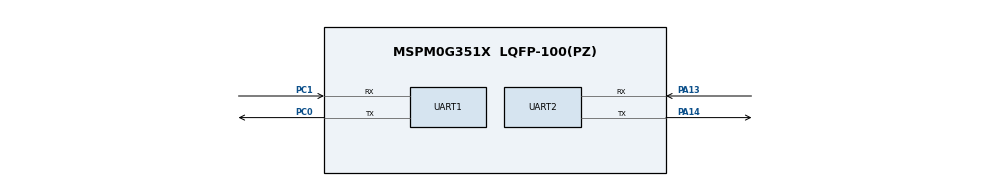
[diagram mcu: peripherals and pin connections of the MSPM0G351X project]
/**
 * @cliArgs --device "MSPM0G351X" --part "Default" --package "LQFP-100(PZ)" --product "mspm0_sdk@2.07.00.05"
 * @versions {"tool":"1.27.0+4565"}
 */

/**
 * Import the modules used in this configuration.
 */
const ADC12         = scripting.addModule("/ti/driverlib/ADC12", {}, false);
const ADC121        = ADC12.addInstance();
const SYSCTL        = scripting.addModule("/ti/driverlib/SYSCTL");
const TIMER         = scripting.addModule("/ti/driverlib/TIMER", {}, false);
const TIMER1        = TIMER.addInstance();
const UART          = scripting.addModule("/ti/driverlib/UART", {}, false);
const UART1         = UART.addInstance();
const UART2         = UART.addInstance();
const ProjectConfig = scripting.addModule("/ti/project_config/ProjectConfig");

/**
 * Write custom configuration values to the imported modules.
 */
const divider9       = system.clockTree["UDIV"];
divider9.divideValue = 2;

const mux4       = system.clockTree["EXHFMUX"];
mux4.inputSelect = "EXHFMUX_XTAL";

const mux8       = system.clockTree["HSCLKMUX"];
mux8.inputSelect = "HSCLKMUX_SYSPLL2X";

const mux12       = system.clockTree["SYSPLLMUX"];
mux12.inputSelect = "zSYSPLLMUX_HFCLK";

const pinFunction4       = system.clockTree["HFXT"];
pinFunction4.inputFreq   = 40;
pinFunction4.enable      = true;
pinFunction4.HFXTStartup = 10;

ADC121.$name                             = "ADC12_0";
ADC121.sampClkSrc                        = "DL_ADC12_CLOCK_ULPCLK";
ADC121.repeatMode                        = true;
ADC121.trigSrc                           = "DL_ADC12_TRIG_SRC_EVENT";
ADC121.adcMem0trig                       = "DL_ADC12_TRIGGER_MODE_TRIGGER_NEXT";
ADC121.powerDownMode                     = "DL_ADC12_POWER_DOWN_MODE_MANUAL";
ADC121.sampleTime0                       = "50 ns";
ADC121.enabledInterrupts                 = ["DL_ADC12_INTERRUPT_DMA_DONE"];
ADC121.configureDMA                      = true;
ADC121.sampCnt                           = 1;
ADC121.enabledDMATriggers                = ["DL_ADC12_DMA_MEM0_RESULT_LOADED"];
ADC121.adcMem0chansel                    = "DL_ADC12_INPUT_CHAN_5";
ADC121.subChanID                         = 1;
ADC121.DMA_CHANNEL.$name                 = "DMA_CH0";
ADC121.DMA_CHANNEL.addressMode           = "f2b";
ADC121.DMA_CHANNEL.srcLength             = "HALF_WORD";
ADC121.DMA_CHANNEL.dstLength             = "HALF_WORD";
ADC121.DMA_CHANNEL.configureTransferSize = true;
ADC121.DMA_CHANNEL.transferMode          = "FULL_CH_REPEAT_SINGLE";
ADC121.DMA_CHANNEL.transferSize          = 1024;
ADC121.adcPin5Config.$name               = "ti_driverlib_gpio_GPIOPinGeneric0";

const Board = scripting.addModule("/ti/driverlib/Board", {}, false);

SYSCTL.forceDefaultClkConfig = true;
SYSCTL.clockTreeEn           = true;

TIMER1.$name                       = "TIMER_0";
TIMER1.timerClkDiv                 = 8;
TIMER1.timerMode                   = "PERIODIC_UP";
TIMER1.timerPeriod                 = "800 ns";
TIMER1.event1PublisherChannel      = 1;
TIMER1.event1ControllerInterruptEn = ["ZERO_EVENT"];

UART1.enabledInterrupts                = ["RX"];
UART1.$name                            = "UART_TJC";
UART1.peripheral.$assign               = "UART1";
UART1.peripheral.rxPin.$assign         = "PC1";
UART1.peripheral.txPin.$assign         = "PC0";
UART1.txPinConfig.$name                = "ti_driverlib_gpio_GPIOPinGeneric1";
UART1.txPinConfig.direction            = scripting.forceWrite("OUTPUT");
UART1.txPinConfig.hideOutputInversion  = scripting.forceWrite(false);
UART1.txPinConfig.onlyInternalResistor = scripting.forceWrite(false);
UART1.txPinConfig.passedPeripheralType = scripting.forceWrite("Digital");
UART1.rxPinConfig.$name                = "ti_driverlib_gpio_GPIOPinGeneric2";
UART1.rxPinConfig.hideOutputInversion  = scripting.forceWrite(false);
UART1.rxPinConfig.onlyInternalResistor = scripting.forceWrite(false);
UART1.rxPinConfig.passedPeripheralType = scripting.forceWrite("Digital");

UART2.$name                            = "UART_HC08";
UART2.peripheral.rxPin.$assign         = "PA13";
UART2.peripheral.txPin.$assign         = "PA14";
UART2.txPinConfig.$name                = "ti_driverlib_gpio_GPIOPinGeneric3";
UART2.txPinConfig.direction            = scripting.forceWrite("OUTPUT");
UART2.txPinConfig.hideOutputInversion  = scripting.forceWrite(false);
UART2.txPinConfig.onlyInternalResistor = scripting.forceWrite(false);
UART2.txPinConfig.passedPeripheralType = scripting.forceWrite("Digital");
UART2.rxPinConfig.$name                = "ti_driverlib_gpio_GPIOPinGeneric4";
UART2.rxPinConfig.hideOutputInversion  = scripting.forceWrite(false);
UART2.rxPinConfig.onlyInternalResistor = scripting.forceWrite(false);
UART2.rxPinConfig.passedPeripheralType = scripting.forceWrite("Digital");

ProjectConfig.genLibCMSIS = true;

/**
 * Pinmux solution for unlocked pins/peripherals. This ensures that minor changes to the automatic solver in a future
 * version of the tool will not impact the pinmux you originally saw.  These lines can be completely deleted in order to
 * re-solve from scratch.
 */
pinFunction4.peripheral.$suggestSolution           = "SYSCTL";
pinFunction4.peripheral.hfxInPin.$suggestSolution  = "PA5";
pinFunction4.peripheral.hfxOutPin.$suggestSolution = "PA6";
ADC121.DMA_CHANNEL.peripheral.$suggestSolution     = "DMA_CH0";
ADC121.peripheral.$suggestSolution                 = "ADC0";
ADC121.peripheral.adcPin5.$suggestSolution         = "PB24";
Board.peripheral.$suggestSolution                  = "DEBUGSS";
Board.peripheral.swclkPin.$suggestSolution         = "PA20";
Board.peripheral.swdioPin.$suggestSolution         = "PA19";
TIMER1.peripheral.$suggestSolution                 = "TIMA0";
UART2.peripheral.$suggestSolution                  = "UART3";
